# CONTROL_MODULE register map
Vendor: Texas Instruments
Registers are 32-bit, access per field, no defined reset value unless marked. A register's access mark holds for its fields unless they carry their own. Offsets are as the file gives them; [hi:lo] are bit positions; {n}, {i} and the like mark numbered series.

## CONTROL_MODULE (part 4 of 5)
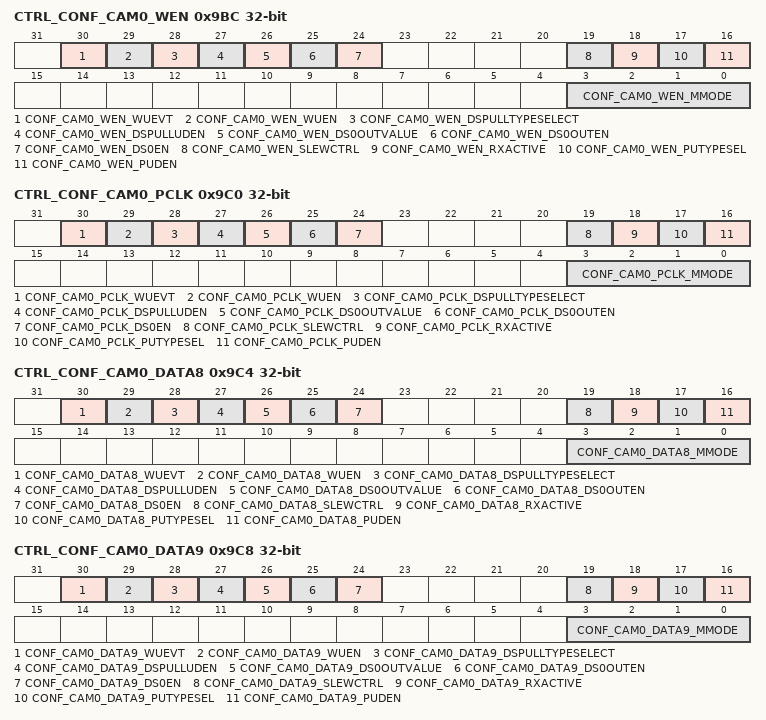
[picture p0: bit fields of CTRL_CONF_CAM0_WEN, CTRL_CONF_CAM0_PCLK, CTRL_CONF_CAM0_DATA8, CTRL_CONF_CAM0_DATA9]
0x9BC CTRL_CONF_CAM0_WEN
  [30] CONF_CAM0_WEN_WUEVT ro — Wakeup Event [[br]]0 = No event [[br]]1 = Event occurred
  [29] CONF_CAM0_WEN_WUEN rw — Wakeup enable [[br]]0 = disable [[br]]1 = enable
  [28] CONF_CAM0_WEN_DSPULLTYPESELECT rw — DS0 mode Pull-Up/Down selection [[br]]0 = Offmode Pull-Down selected [[br]]1 = Offmode Pull-Up selected
  [27] CONF_CAM0_WEN_DSPULLUDEN rw — DS0 mode Pull-Up/Down enable. [[br]]This is an active low signal. [[br]]1 = Pullup / Pulldown disabled [[br]]0 = Pullup / Pulldown enabled
  [26] CONF_CAM0_WEN_DS0OUTVALUE rw — DS0 mode output value [[br]]0 = Set value at 0 [[br]]1 = Set value at 1
  [25] CONF_CAM0_WEN_DS0OUTEN rw — DS0 mode output enable This is an active low signal [[br]]0 = Output Enable [[br]]1 = Output Disable
  [24] CONF_CAM0_WEN_DS0EN rw — DS0 mode override control [[br]]0: IO state keeps its previous state when DS0 mode is active [[br]]1: IO state is forced to OFF mode value when DS0 mode is active
  [19] CONF_CAM0_WEN_SLEWCTRL rw — Select between Faster or Slower Slew rate [[br]]0 = fast [[br]]1 = slow
  [18] CONF_CAM0_WEN_RXACTIVE rw — Input Enable Value for the PAD [[br]]0 = receiver disabled [[br]]1 = receiver enabled
  [17] CONF_CAM0_WEN_PUTYPESEL rw — Pad Pullup / Pulldown Type Selection [[br]]0 = Pulldown selected [[br]]1 = Pullup selected
  [16] CONF_CAM0_WEN_PUDEN rw — Pad Pullup / Pulldown Enable. [[br]]This is an active low signal [[br]]1 = Pullup / Pulldown disabled [[br]]0 = Pullup / Pulldown enabled
  [3:0] CONF_CAM0_WEN_MMODE rw — Pad Functional Signal Mux Select
0x9C0 CTRL_CONF_CAM0_PCLK
  [30] CONF_CAM0_PCLK_WUEVT ro — Wakeup Event [[br]]0 = No event [[br]]1 = Event occurred
  [29] CONF_CAM0_PCLK_WUEN rw — Wakeup enable [[br]]0 = disable [[br]]1 = enable
  [28] CONF_CAM0_PCLK_DSPULLTYPESELECT rw — DS0 mode Pull-Up/Down selection [[br]]0 = Offmode Pull-Down selected [[br]]1 = Offmode Pull-Up selected
  [27] CONF_CAM0_PCLK_DSPULLUDEN rw — DS0 mode Pull-Up/Down enable. [[br]]This is an active low signal. [[br]]1 = Pullup / Pulldown disabled [[br]]0 = Pullup / Pulldown enabled
  [26] CONF_CAM0_PCLK_DS0OUTVALUE rw — DS0 mode output value [[br]]0 = Set value at 0 [[br]]1 = Set value at 1
  [25] CONF_CAM0_PCLK_DS0OUTEN rw — DS0 mode output enable This is an active low signal [[br]]0 = Output Enable [[br]]1 = Output Disable
  [24] CONF_CAM0_PCLK_DS0EN rw — DS0 mode override control [[br]]0: IO state keeps its previous state when DS0 mode is active [[br]]1: IO state is forced to OFF mode value when DS0 mode is active
  [19] CONF_CAM0_PCLK_SLEWCTRL rw — Select between Faster or Slower Slew rate [[br]]0 = fast [[br]]1 = slow
  [18] CONF_CAM0_PCLK_RXACTIVE rw — Input Enable Value for the PAD [[br]]0 = receiver disabled [[br]]1 = receiver enabled
  [17] CONF_CAM0_PCLK_PUTYPESEL rw — Pad Pullup / Pulldown Type Selection [[br]]0 = Pulldown selected [[br]]1 = Pullup selected
  [16] CONF_CAM0_PCLK_PUDEN rw — Pad Pullup / Pulldown Enable. [[br]]This is an active low signal [[br]]1 = Pullup / Pulldown disabled [[br]]0 = Pullup / Pulldown enabled
  [3:0] CONF_CAM0_PCLK_MMODE rw — Pad Functional Signal Mux Select
0x9C4 CTRL_CONF_CAM0_DATA8
  [30] CONF_CAM0_DATA8_WUEVT ro — Wakeup Event [[br]]0 = No event [[br]]1 = Event occurred
  [29] CONF_CAM0_DATA8_WUEN rw — Wakeup enable [[br]]0 = disable [[br]]1 = enable
  [28] CONF_CAM0_DATA8_DSPULLTYPESELECT rw — DS0 mode Pull-Up/Down selection [[br]]0 = Offmode Pull-Down selected [[br]]1 = Offmode Pull-Up selected
  [27] CONF_CAM0_DATA8_DSPULLUDEN rw — DS0 mode Pull-Up/Down enable. [[br]]This is an active low signal. [[br]]1 = Pullup / Pulldown disabled [[br]]0 = Pullup / Pulldown enabled
  [26] CONF_CAM0_DATA8_DS0OUTVALUE rw — DS0 mode output value [[br]]0 = Set value at 0 [[br]]1 = Set value at 1
  [25] CONF_CAM0_DATA8_DS0OUTEN rw — DS0 mode output enable This is an active low signal [[br]]0 = Output Enable [[br]]1 = Output Disable
  [24] CONF_CAM0_DATA8_DS0EN rw — DS0 mode override control [[br]]0: IO state keeps its previous state when DS0 mode is active [[br]]1: IO state is forced to OFF mode value when DS0 mode is active
  [19] CONF_CAM0_DATA8_SLEWCTRL rw — Select between Faster or Slower Slew rate [[br]]0 = fast [[br]]1 = slow
  [18] CONF_CAM0_DATA8_RXACTIVE rw — Input Enable Value for the PAD [[br]]0 = receiver disabled [[br]]1 = receiver enabled
  [17] CONF_CAM0_DATA8_PUTYPESEL rw — Pad Pullup / Pulldown Type Selection [[br]]0 = Pulldown selected [[br]]1 = Pullup selected
  [16] CONF_CAM0_DATA8_PUDEN rw — Pad Pullup / Pulldown Enable. [[br]]This is an active low signal [[br]]1 = Pullup / Pulldown disabled [[br]]0 = Pullup / Pulldown enabled
  [3:0] CONF_CAM0_DATA8_MMODE rw — Pad Functional Signal Mux Select
0x9C8 CTRL_CONF_CAM0_DATA9
  [30] CONF_CAM0_DATA9_WUEVT ro — Wakeup Event [[br]]0 = No event [[br]]1 = Event occurred
  [29] CONF_CAM0_DATA9_WUEN rw — Wakeup enable [[br]]0 = disable [[br]]1 = enable
  [28] CONF_CAM0_DATA9_DSPULLTYPESELECT rw — DS0 mode Pull-Up/Down selection [[br]]0 = Offmode Pull-Down selected [[br]]1 = Offmode Pull-Up selected
  [27] CONF_CAM0_DATA9_DSPULLUDEN rw — DS0 mode Pull-Up/Down enable. [[br]]This is an active low signal. [[br]]1 = Pullup / Pulldown disabled [[br]]0 = Pullup / Pulldown enabled
  [26] CONF_CAM0_DATA9_DS0OUTVALUE rw — DS0 mode output value [[br]]0 = Set value at 0 [[br]]1 = Set value at 1
  [25] CONF_CAM0_DATA9_DS0OUTEN rw — DS0 mode output enable This is an active low signal [[br]]0 = Output Enable [[br]]1 = Output Disable
  [24] CONF_CAM0_DATA9_DS0EN rw — DS0 mode override control [[br]]0: IO state keeps its previous state when DS0 mode is active [[br]]1: IO state is forced to OFF mode value when DS0 mode is active
  [19] CONF_CAM0_DATA9_SLEWCTRL rw — Select between Faster or Slower Slew rate [[br]]0 = fast [[br]]1 = slow
  [18] CONF_CAM0_DATA9_RXACTIVE rw — Input Enable Value for the PAD [[br]]0 = receiver disabled [[br]]1 = receiver enabled
  [17] CONF_CAM0_DATA9_PUTYPESEL rw — Pad Pullup / Pulldown Type Selection [[br]]0 = Pulldown selected [[br]]1 = Pullup selected
  [16] CONF_CAM0_DATA9_PUDEN rw — Pad Pullup / Pulldown Enable. [[br]]This is an active low signal [[br]]1 = Pullup / Pulldown disabled [[br]]0 = Pullup / Pulldown enabled
  [3:0] CONF_CAM0_DATA9_MMODE rw — Pad Functional Signal Mux Select
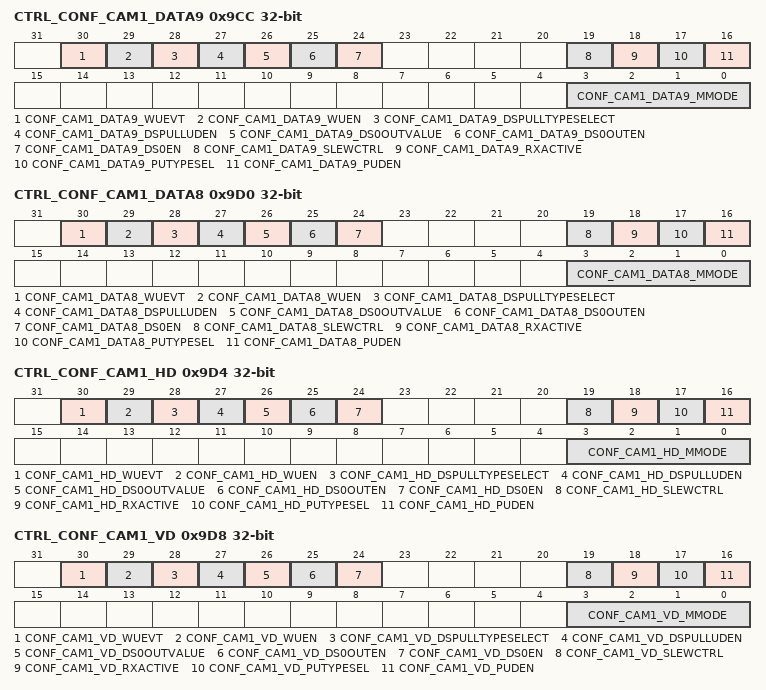
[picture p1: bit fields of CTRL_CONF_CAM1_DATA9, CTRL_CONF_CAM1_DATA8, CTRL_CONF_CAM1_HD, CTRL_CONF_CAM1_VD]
0x9CC CTRL_CONF_CAM1_DATA9
  [30] CONF_CAM1_DATA9_WUEVT ro — Wakeup Event [[br]]0 = No event [[br]]1 = Event occurred
  [29] CONF_CAM1_DATA9_WUEN rw — Wakeup enable [[br]]0 = disable [[br]]1 = enable
  [28] CONF_CAM1_DATA9_DSPULLTYPESELECT rw — DS0 mode Pull-Up/Down selection [[br]]0 = Offmode Pull-Down selected [[br]]1 = Offmode Pull-Up selected
  [27] CONF_CAM1_DATA9_DSPULLUDEN rw — DS0 mode Pull-Up/Down enable. [[br]]This is an active low signal. [[br]]1 = Pullup / Pulldown disabled [[br]]0 = Pullup / Pulldown enabled
  [26] CONF_CAM1_DATA9_DS0OUTVALUE rw — DS0 mode output value [[br]]0 = Set value at 0 [[br]]1 = Set value at 1
  [25] CONF_CAM1_DATA9_DS0OUTEN rw — DS0 mode output enable This is an active low signal [[br]]0 = Output Enable [[br]]1 = Output Disable
  [24] CONF_CAM1_DATA9_DS0EN rw — DS0 mode override control [[br]]0: IO state keeps its previous state when DS0 mode is active [[br]]1: IO state is forced to OFF mode value when DS0 mode is active
  [19] CONF_CAM1_DATA9_SLEWCTRL rw — Select between Faster or Slower Slew rate [[br]]0 = fast [[br]]1 = slow
  [18] CONF_CAM1_DATA9_RXACTIVE rw — Input Enable Value for the PAD [[br]]0 = receiver disabled [[br]]1 = receiver enabled
  [17] CONF_CAM1_DATA9_PUTYPESEL rw — Pad Pullup / Pulldown Type Selection [[br]]0 = Pulldown selected [[br]]1 = Pullup selected
  [16] CONF_CAM1_DATA9_PUDEN rw — Pad Pullup / Pulldown Enable. [[br]]This is an active low signal [[br]]1 = Pullup / Pulldown disabled [[br]]0 = Pullup / Pulldown enabled
  [3:0] CONF_CAM1_DATA9_MMODE rw — Pad Functional Signal Mux Select
0x9D0 CTRL_CONF_CAM1_DATA8
  [30] CONF_CAM1_DATA8_WUEVT ro — Wakeup Event [[br]]0 = No event [[br]]1 = Event occurred
  [29] CONF_CAM1_DATA8_WUEN rw — Wakeup enable [[br]]0 = disable [[br]]1 = enable
  [28] CONF_CAM1_DATA8_DSPULLTYPESELECT rw — DS0 mode Pull-Up/Down selection [[br]]0 = Offmode Pull-Down selected [[br]]1 = Offmode Pull-Up selected
  [27] CONF_CAM1_DATA8_DSPULLUDEN rw — DS0 mode Pull-Up/Down enable. [[br]]This is an active low signal. [[br]]1 = Pullup / Pulldown disabled [[br]]0 = Pullup / Pulldown enabled
  [26] CONF_CAM1_DATA8_DS0OUTVALUE rw — DS0 mode output value [[br]]0 = Set value at 0 [[br]]1 = Set value at 1
  [25] CONF_CAM1_DATA8_DS0OUTEN rw — DS0 mode output enable This is an active low signal [[br]]0 = Output Enable [[br]]1 = Output Disable
  [24] CONF_CAM1_DATA8_DS0EN rw — DS0 mode override control [[br]]0: IO state keeps its previous state when DS0 mode is active [[br]]1: IO state is forced to OFF mode value when DS0 mode is active
  [19] CONF_CAM1_DATA8_SLEWCTRL rw — Select between Faster or Slower Slew rate [[br]]0 = fast [[br]]1 = slow
  [18] CONF_CAM1_DATA8_RXACTIVE rw — Input Enable Value for the PAD [[br]]0 = receiver disabled [[br]]1 = receiver enabled
  [17] CONF_CAM1_DATA8_PUTYPESEL rw — Pad Pullup / Pulldown Type Selection [[br]]0 = Pulldown selected [[br]]1 = Pullup selected
  [16] CONF_CAM1_DATA8_PUDEN rw — Pad Pullup / Pulldown Enable. [[br]]This is an active low signal [[br]]1 = Pullup / Pulldown disabled [[br]]0 = Pullup / Pulldown enabled
  [3:0] CONF_CAM1_DATA8_MMODE rw — Pad Functional Signal Mux Select
0x9D4 CTRL_CONF_CAM1_HD
  [30] CONF_CAM1_HD_WUEVT ro — Wakeup Event [[br]]0 = No event [[br]]1 = Event occurred
  [29] CONF_CAM1_HD_WUEN rw — Wakeup enable [[br]]0 = disable [[br]]1 = enable
  [28] CONF_CAM1_HD_DSPULLTYPESELECT rw — DS0 mode Pull-Up/Down selection [[br]]0 = Offmode Pull-Down selected [[br]]1 = Offmode Pull-Up selected
  [27] CONF_CAM1_HD_DSPULLUDEN rw — DS0 mode Pull-Up/Down enable. [[br]]This is an active low signal. [[br]]1 = Pullup / Pulldown disabled [[br]]0 = Pullup / Pulldown enabled
  [26] CONF_CAM1_HD_DS0OUTVALUE rw — DS0 mode output value [[br]]0 = Set value at 0 [[br]]1 = Set value at 1
  [25] CONF_CAM1_HD_DS0OUTEN rw — DS0 mode output enable This is an active low signal [[br]]0 = Output Enable [[br]]1 = Output Disable
  [24] CONF_CAM1_HD_DS0EN rw — DS0 mode override control [[br]]0: IO state keeps its previous state when DS0 mode is active [[br]]1: IO state is forced to OFF mode value when DS0 mode is active
  [19] CONF_CAM1_HD_SLEWCTRL rw — Select between Faster or Slower Slew rate [[br]]0 = fast [[br]]1 = slow
  [18] CONF_CAM1_HD_RXACTIVE rw — Input Enable Value for the PAD [[br]]0 = receiver disabled [[br]]1 = receiver enabled
  [17] CONF_CAM1_HD_PUTYPESEL rw — Pad Pullup / Pulldown Type Selection [[br]]0 = Pulldown selected [[br]]1 = Pullup selected
  [16] CONF_CAM1_HD_PUDEN rw — Pad Pullup / Pulldown Enable. [[br]]This is an active low signal [[br]]1 = Pullup / Pulldown disabled [[br]]0 = Pullup / Pulldown enabled
  [3:0] CONF_CAM1_HD_MMODE rw — Pad Functional Signal Mux Select
0x9D8 CTRL_CONF_CAM1_VD
  [30] CONF_CAM1_VD_WUEVT ro — Wakeup Event [[br]]0 = No event [[br]]1 = Event occurred
  [29] CONF_CAM1_VD_WUEN rw — Wakeup enable [[br]]0 = disable [[br]]1 = enable
  [28] CONF_CAM1_VD_DSPULLTYPESELECT rw — DS0 mode Pull-Up/Down selection [[br]]0 = Offmode Pull-Down selected [[br]]1 = Offmode Pull-Up selected
  [27] CONF_CAM1_VD_DSPULLUDEN rw — DS0 mode Pull-Up/Down enable. [[br]]This is an active low signal. [[br]]1 = Pullup / Pulldown disabled [[br]]0 = Pullup / Pulldown enabled
  [26] CONF_CAM1_VD_DS0OUTVALUE rw — DS0 mode output value [[br]]0 = Set value at 0 [[br]]1 = Set value at 1
  [25] CONF_CAM1_VD_DS0OUTEN rw — DS0 mode output enable This is an active low signal [[br]]0 = Output Enable [[br]]1 = Output Disable
  [24] CONF_CAM1_VD_DS0EN rw — DS0 mode override control [[br]]0: IO state keeps its previous state when DS0 mode is active [[br]]1: IO state is forced to OFF mode value when DS0 mode is active
  [19] CONF_CAM1_VD_SLEWCTRL rw — Select between Faster or Slower Slew rate [[br]]0 = fast [[br]]1 = slow
  [18] CONF_CAM1_VD_RXACTIVE rw — Input Enable Value for the PAD [[br]]0 = receiver disabled [[br]]1 = receiver enabled
  [17] CONF_CAM1_VD_PUTYPESEL rw — Pad Pullup / Pulldown Type Selection [[br]]0 = Pulldown selected [[br]]1 = Pullup selected
  [16] CONF_CAM1_VD_PUDEN rw — Pad Pullup / Pulldown Enable. [[br]]This is an active low signal [[br]]1 = Pullup / Pulldown disabled [[br]]0 = Pullup / Pulldown enabled
  [3:0] CONF_CAM1_VD_MMODE rw — Pad Functional Signal Mux Select
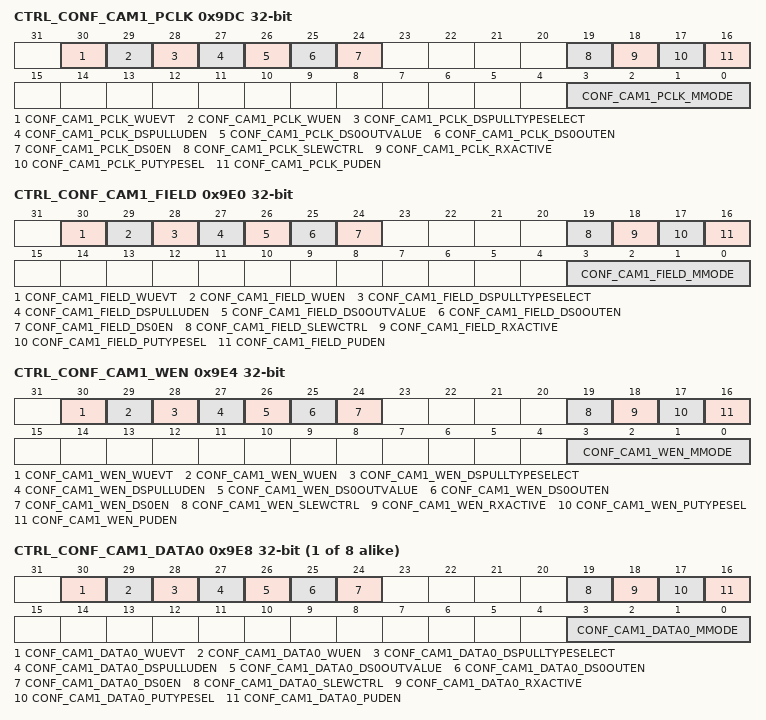
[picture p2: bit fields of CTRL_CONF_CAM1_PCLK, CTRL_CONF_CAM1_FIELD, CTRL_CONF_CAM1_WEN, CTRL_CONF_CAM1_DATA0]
0x9DC CTRL_CONF_CAM1_PCLK
  [30] CONF_CAM1_PCLK_WUEVT ro — Wakeup Event [[br]]0 = No event [[br]]1 = Event occurred
  [29] CONF_CAM1_PCLK_WUEN rw — Wakeup enable [[br]]0 = disable [[br]]1 = enable
  [28] CONF_CAM1_PCLK_DSPULLTYPESELECT rw — DS0 mode Pull-Up/Down selection [[br]]0 = Offmode Pull-Down selected [[br]]1 = Offmode Pull-Up selected
  [27] CONF_CAM1_PCLK_DSPULLUDEN rw — DS0 mode Pull-Up/Down enable. [[br]]This is an active low signal. [[br]]1 = Pullup / Pulldown disabled [[br]]0 = Pullup / Pulldown enabled
  [26] CONF_CAM1_PCLK_DS0OUTVALUE rw — DS0 mode output value [[br]]0 = Set value at 0 [[br]]1 = Set value at 1
  [25] CONF_CAM1_PCLK_DS0OUTEN rw — DS0 mode output enable This is an active low signal [[br]]0 = Output Enable [[br]]1 = Output Disable
  [24] CONF_CAM1_PCLK_DS0EN rw — DS0 mode override control [[br]]0: IO state keeps its previous state when DS0 mode is active [[br]]1: IO state is forced to OFF mode value when DS0 mode is active
  [19] CONF_CAM1_PCLK_SLEWCTRL rw — Select between Faster or Slower Slew rate [[br]]0 = fast [[br]]1 = slow
  [18] CONF_CAM1_PCLK_RXACTIVE rw — Input Enable Value for the PAD [[br]]0 = receiver disabled [[br]]1 = receiver enabled
  [17] CONF_CAM1_PCLK_PUTYPESEL rw — Pad Pullup / Pulldown Type Selection [[br]]0 = Pulldown selected [[br]]1 = Pullup selected
  [16] CONF_CAM1_PCLK_PUDEN rw — Pad Pullup / Pulldown Enable. [[br]]This is an active low signal [[br]]1 = Pullup / Pulldown disabled [[br]]0 = Pullup / Pulldown enabled
  [3:0] CONF_CAM1_PCLK_MMODE rw — Pad Functional Signal Mux Select
0x9E0 CTRL_CONF_CAM1_FIELD
  [30] CONF_CAM1_FIELD_WUEVT ro — Wakeup Event [[br]]0 = No event [[br]]1 = Event occurred
  [29] CONF_CAM1_FIELD_WUEN rw — Wakeup enable [[br]]0 = disable [[br]]1 = enable
  [28] CONF_CAM1_FIELD_DSPULLTYPESELECT rw — DS0 mode Pull-Up/Down selection [[br]]0 = Offmode Pull-Down selected [[br]]1 = Offmode Pull-Up selected
  [27] CONF_CAM1_FIELD_DSPULLUDEN rw — DS0 mode Pull-Up/Down enable. [[br]]This is an active low signal. [[br]]1 = Pullup / Pulldown disabled [[br]]0 = Pullup / Pulldown enabled
  [26] CONF_CAM1_FIELD_DS0OUTVALUE rw — DS0 mode output value [[br]]0 = Set value at 0 [[br]]1 = Set value at 1
  [25] CONF_CAM1_FIELD_DS0OUTEN rw — DS0 mode output enable This is an active low signal [[br]]0 = Output Enable [[br]]1 = Output Disable
  [24] CONF_CAM1_FIELD_DS0EN rw — DS0 mode override control [[br]]0: IO state keeps its previous state when DS0 mode is active [[br]]1: IO state is forced to OFF mode value when DS0 mode is active
  [19] CONF_CAM1_FIELD_SLEWCTRL rw — Select between Faster or Slower Slew rate [[br]]0 = fast [[br]]1 = slow
  [18] CONF_CAM1_FIELD_RXACTIVE rw — Input Enable Value for the PAD [[br]]0 = receiver disabled [[br]]1 = receiver enabled
  [17] CONF_CAM1_FIELD_PUTYPESEL rw — Pad Pullup / Pulldown Type Selection [[br]]0 = Pulldown selected [[br]]1 = Pullup selected
  [16] CONF_CAM1_FIELD_PUDEN rw — Pad Pullup / Pulldown Enable. [[br]]This is an active low signal [[br]]1 = Pullup / Pulldown disabled [[br]]0 = Pullup / Pulldown enabled
  [3:0] CONF_CAM1_FIELD_MMODE rw — Pad Functional Signal Mux Select
0x9E4 CTRL_CONF_CAM1_WEN
  [30] CONF_CAM1_WEN_WUEVT ro — Wakeup Event [[br]]0 = No event [[br]]1 = Event occurred
  [29] CONF_CAM1_WEN_WUEN rw — Wakeup enable [[br]]0 = disable [[br]]1 = enable
  [28] CONF_CAM1_WEN_DSPULLTYPESELECT rw — DS0 mode Pull-Up/Down selection [[br]]0 = Offmode Pull-Down selected [[br]]1 = Offmode Pull-Up selected
  [27] CONF_CAM1_WEN_DSPULLUDEN rw — DS0 mode Pull-Up/Down enable. [[br]]This is an active low signal. [[br]]1 = Pullup / Pulldown disabled [[br]]0 = Pullup / Pulldown enabled
  [26] CONF_CAM1_WEN_DS0OUTVALUE rw — DS0 mode output value [[br]]0 = Set value at 0 [[br]]1 = Set value at 1
  [25] CONF_CAM1_WEN_DS0OUTEN rw — DS0 mode output enable This is an active low signal [[br]]0 = Output Enable [[br]]1 = Output Disable
  [24] CONF_CAM1_WEN_DS0EN rw — DS0 mode override control [[br]]0: IO state keeps its previous state when DS0 mode is active [[br]]1: IO state is forced to OFF mode value when DS0 mode is active
  [19] CONF_CAM1_WEN_SLEWCTRL rw — Select between Faster or Slower Slew rate [[br]]0 = fast [[br]]1 = slow
  [18] CONF_CAM1_WEN_RXACTIVE rw — Input Enable Value for the PAD [[br]]0 = receiver disabled [[br]]1 = receiver enabled
  [17] CONF_CAM1_WEN_PUTYPESEL rw — Pad Pullup / Pulldown Type Selection [[br]]0 = Pulldown selected [[br]]1 = Pullup selected
  [16] CONF_CAM1_WEN_PUDEN rw — Pad Pullup / Pulldown Enable. [[br]]This is an active low signal [[br]]1 = Pullup / Pulldown disabled [[br]]0 = Pullup / Pulldown enabled
  [3:0] CONF_CAM1_WEN_MMODE rw — Pad Functional Signal Mux Select
{0x9E8+4i} CTRL_CONF_CAM1_DATA{i} (i=0..7)
  [30] CONF_CAM1_DATA{i}_WUEVT ro — Wakeup Event [[br]]0 = No event [[br]]1 = Event occurred
  [29] CONF_CAM1_DATA{i}_WUEN rw — Wakeup enable [[br]]0 = disable [[br]]1 = enable
  [28] CONF_CAM1_DATA{i}_DSPULLTYPESELECT rw — DS0 mode Pull-Up/Down selection [[br]]0 = Offmode Pull-Down selected [[br]]1 = Offmode Pull-Up selected
  [27] CONF_CAM1_DATA{i}_DSPULLUDEN rw — DS0 mode Pull-Up/Down enable. [[br]]This is an active low signal. [[br]]1 = Pullup / Pulldown disabled [[br]]0 = Pullup / Pulldown enabled
  [26] CONF_CAM1_DATA{i}_DS0OUTVALUE rw — DS0 mode output value [[br]]0 = Set value at 0 [[br]]1 = Set value at 1
  [25] CONF_CAM1_DATA{i}_DS0OUTEN rw — DS0 mode output enable This is an active low signal [[br]]0 = Output Enable [[br]]1 = Output Disable
  [24] CONF_CAM1_DATA{i}_DS0EN rw — DS0 mode override control [[br]]0: IO state keeps its previous state when DS0 mode is active [[br]]1: IO state is forced to OFF mode value when DS0 mode is active
  [19] CONF_CAM1_DATA{i}_SLEWCTRL rw — Select between Faster or Slower Slew rate [[br]]0 = fast [[br]]1 = slow
  [18] CONF_CAM1_DATA{i}_RXACTIVE rw — Input Enable Value for the PAD [[br]]0 = receiver disabled [[br]]1 = receiver enabled
  [17] CONF_CAM1_DATA{i}_PUTYPESEL rw — Pad Pullup / Pulldown Type Selection [[br]]0 = Pulldown selected [[br]]1 = Pullup selected
  [16] CONF_CAM1_DATA{i}_PUDEN rw — Pad Pullup / Pulldown Enable. [[br]]This is an active low signal [[br]]1 = Pullup / Pulldown disabled [[br]]0 = Pullup / Pulldown enabled
  [3:0] CONF_CAM1_DATA{i}_MMODE rw — Pad Functional Signal Mux Select
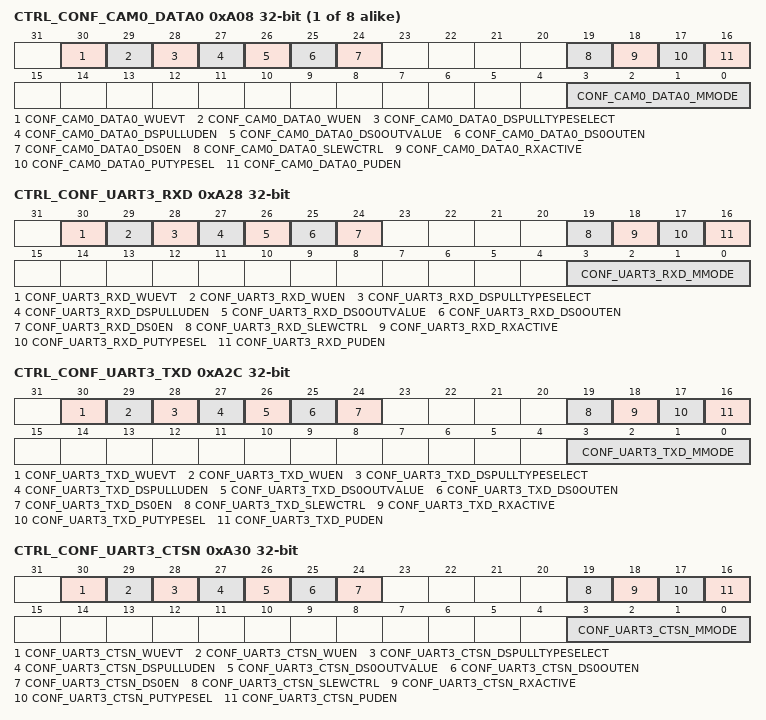
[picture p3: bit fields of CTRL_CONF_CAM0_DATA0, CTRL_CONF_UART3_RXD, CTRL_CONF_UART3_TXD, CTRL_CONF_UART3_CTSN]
{0xA08+4i} CTRL_CONF_CAM0_DATA{i} (i=0..7)
  [30] CONF_CAM0_DATA{i}_WUEVT ro — Wakeup Event [[br]]0 = No event [[br]]1 = Event occurred
  [29] CONF_CAM0_DATA{i}_WUEN rw — Wakeup enable [[br]]0 = disable [[br]]1 = enable
  [28] CONF_CAM0_DATA{i}_DSPULLTYPESELECT rw — DS0 mode Pull-Up/Down selection [[br]]0 = Offmode Pull-Down selected [[br]]1 = Offmode Pull-Up selected
  [27] CONF_CAM0_DATA{i}_DSPULLUDEN rw — DS0 mode Pull-Up/Down enable. [[br]]This is an active low signal. [[br]]1 = Pullup / Pulldown disabled [[br]]0 = Pullup / Pulldown enabled
  [26] CONF_CAM0_DATA{i}_DS0OUTVALUE rw — DS0 mode output value [[br]]0 = Set value at 0 [[br]]1 = Set value at 1
  [25] CONF_CAM0_DATA{i}_DS0OUTEN rw — DS0 mode output enable This is an active low signal [[br]]0 = Output Enable [[br]]1 = Output Disable
  [24] CONF_CAM0_DATA{i}_DS0EN rw — DS0 mode override control [[br]]0: IO state keeps its previous state when DS0 mode is active [[br]]1: IO state is forced to OFF mode value when DS0 mode is active
  [19] CONF_CAM0_DATA{i}_SLEWCTRL rw — Select between Faster or Slower Slew rate [[br]]0 = fast [[br]]1 = slow
  [18] CONF_CAM0_DATA{i}_RXACTIVE rw — Input Enable Value for the PAD [[br]]0 = receiver disabled [[br]]1 = receiver enabled
  [17] CONF_CAM0_DATA{i}_PUTYPESEL rw — Pad Pullup / Pulldown Type Selection [[br]]0 = Pulldown selected [[br]]1 = Pullup selected
  [16] CONF_CAM0_DATA{i}_PUDEN rw — Pad Pullup / Pulldown Enable. [[br]]This is an active low signal [[br]]1 = Pullup / Pulldown disabled [[br]]0 = Pullup / Pulldown enabled
  [3:0] CONF_CAM0_DATA{i}_MMODE rw — Pad Functional Signal Mux Select
0xA28 CTRL_CONF_UART3_RXD
  [30] CONF_UART3_RXD_WUEVT ro — Wakeup Event [[br]]0 = No event [[br]]1 = Event occurred
  [29] CONF_UART3_RXD_WUEN rw — Wakeup enable [[br]]0 = disable [[br]]1 = enable
  [28] CONF_UART3_RXD_DSPULLTYPESELECT rw — DS0 mode Pull-Up/Down selection [[br]]0 = Offmode Pull-Down selected [[br]]1 = Offmode Pull-Up selected
  [27] CONF_UART3_RXD_DSPULLUDEN rw — DS0 mode Pull-Up/Down enable. [[br]]This is an active low signal. [[br]]1 = Pullup / Pulldown disabled [[br]]0 = Pullup / Pulldown enabled
  [26] CONF_UART3_RXD_DS0OUTVALUE rw — DS0 mode output value [[br]]0 = Set value at 0 [[br]]1 = Set value at 1
  [25] CONF_UART3_RXD_DS0OUTEN rw — DS0 mode output enable This is an active low signal [[br]]0 = Output Enable [[br]]1 = Output Disable
  [24] CONF_UART3_RXD_DS0EN rw — DS0 mode override control [[br]]0: IO state keeps its previous state when DS0 mode is active [[br]]1: IO state is forced to OFF mode value when DS0 mode is active
  [19] CONF_UART3_RXD_SLEWCTRL rw — Select between Faster or Slower Slew rate [[br]]0 = fast [[br]]1 = slow
  [18] CONF_UART3_RXD_RXACTIVE rw — Input Enable Value for the PAD [[br]]0 = receiver disabled [[br]]1 = receiver enabled
  [17] CONF_UART3_RXD_PUTYPESEL rw — Pad Pullup / Pulldown Type Selection [[br]]0 = Pulldown selected [[br]]1 = Pullup selected
  [16] CONF_UART3_RXD_PUDEN rw — Pad Pullup / Pulldown Enable. [[br]]This is an active low signal [[br]]1 = Pullup / Pulldown disabled [[br]]0 = Pullup / Pulldown enabled
  [3:0] CONF_UART3_RXD_MMODE rw — Pad Functional Signal Mux Select
0xA2C CTRL_CONF_UART3_TXD
  [30] CONF_UART3_TXD_WUEVT ro — Wakeup Event [[br]]0 = No event [[br]]1 = Event occurred
  [29] CONF_UART3_TXD_WUEN rw — Wakeup enable [[br]]0 = disable [[br]]1 = enable
  [28] CONF_UART3_TXD_DSPULLTYPESELECT rw — DS0 mode Pull-Up/Down selection [[br]]0 = Offmode Pull-Down selected [[br]]1 = Offmode Pull-Up selected
  [27] CONF_UART3_TXD_DSPULLUDEN rw — DS0 mode Pull-Up/Down enable. [[br]]This is an active low signal. [[br]]1 = Pullup / Pulldown disabled [[br]]0 = Pullup / Pulldown enabled
  [26] CONF_UART3_TXD_DS0OUTVALUE rw — DS0 mode output value [[br]]0 = Set value at 0 [[br]]1 = Set value at 1
  [25] CONF_UART3_TXD_DS0OUTEN rw — DS0 mode output enable This is an active low signal [[br]]0 = Output Enable [[br]]1 = Output Disable
  [24] CONF_UART3_TXD_DS0EN rw — DS0 mode override control [[br]]0: IO state keeps its previous state when DS0 mode is active [[br]]1: IO state is forced to OFF mode value when DS0 mode is active
  [19] CONF_UART3_TXD_SLEWCTRL rw — Select between Faster or Slower Slew rate [[br]]0 = fast [[br]]1 = slow
  [18] CONF_UART3_TXD_RXACTIVE rw — Input Enable Value for the PAD [[br]]0 = receiver disabled [[br]]1 = receiver enabled
  [17] CONF_UART3_TXD_PUTYPESEL rw — Pad Pullup / Pulldown Type Selection [[br]]0 = Pulldown selected [[br]]1 = Pullup selected
  [16] CONF_UART3_TXD_PUDEN rw — Pad Pullup / Pulldown Enable. [[br]]This is an active low signal [[br]]1 = Pullup / Pulldown disabled [[br]]0 = Pullup / Pulldown enabled
  [3:0] CONF_UART3_TXD_MMODE rw — Pad Functional Signal Mux Select
0xA30 CTRL_CONF_UART3_CTSN
  [30] CONF_UART3_CTSN_WUEVT ro — Wakeup Event [[br]]0 = No event [[br]]1 = Event occurred
  [29] CONF_UART3_CTSN_WUEN rw — Wakeup enable [[br]]0 = disable [[br]]1 = enable
  [28] CONF_UART3_CTSN_DSPULLTYPESELECT rw — DS0 mode Pull-Up/Down selection [[br]]0 = Offmode Pull-Down selected [[br]]1 = Offmode Pull-Up selected
  [27] CONF_UART3_CTSN_DSPULLUDEN rw — DS0 mode Pull-Up/Down enable. [[br]]This is an active low signal. [[br]]1 = Pullup / Pulldown disabled [[br]]0 = Pullup / Pulldown enabled
  [26] CONF_UART3_CTSN_DS0OUTVALUE rw — DS0 mode output value [[br]]0 = Set value at 0 [[br]]1 = Set value at 1
  [25] CONF_UART3_CTSN_DS0OUTEN rw — DS0 mode output enable This is an active low signal [[br]]0 = Output Enable [[br]]1 = Output Disable
  [24] CONF_UART3_CTSN_DS0EN rw — DS0 mode override control [[br]]0: IO state keeps its previous state when DS0 mode is active [[br]]1: IO state is forced to OFF mode value when DS0 mode is active
  [19] CONF_UART3_CTSN_SLEWCTRL rw — Select between Faster or Slower Slew rate [[br]]0 = fast [[br]]1 = slow
  [18] CONF_UART3_CTSN_RXACTIVE rw — Input Enable Value for the PAD [[br]]0 = receiver disabled [[br]]1 = receiver enabled
  [17] CONF_UART3_CTSN_PUTYPESEL rw — Pad Pullup / Pulldown Type Selection [[br]]0 = Pulldown selected [[br]]1 = Pullup selected
  [16] CONF_UART3_CTSN_PUDEN rw — Pad Pullup / Pulldown Enable. [[br]]This is an active low signal [[br]]1 = Pullup / Pulldown disabled [[br]]0 = Pullup / Pulldown enabled
  [3:0] CONF_UART3_CTSN_MMODE rw — Pad Functional Signal Mux Select
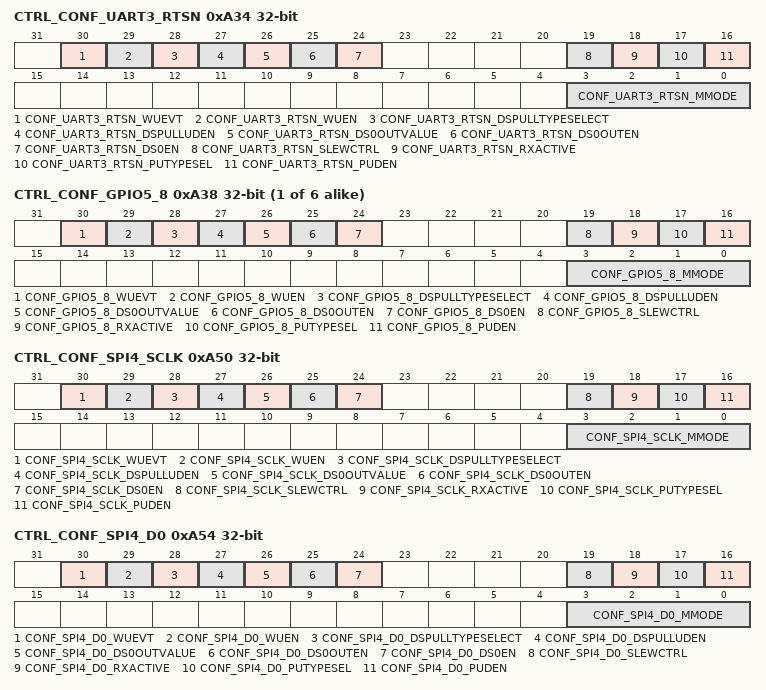
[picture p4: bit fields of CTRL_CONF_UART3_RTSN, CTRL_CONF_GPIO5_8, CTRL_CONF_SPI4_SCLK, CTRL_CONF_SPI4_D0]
0xA34 CTRL_CONF_UART3_RTSN
  [30] CONF_UART3_RTSN_WUEVT ro — Wakeup Event [[br]]0 = No event [[br]]1 = Event occurred
  [29] CONF_UART3_RTSN_WUEN rw — Wakeup enable [[br]]0 = disable [[br]]1 = enable
  [28] CONF_UART3_RTSN_DSPULLTYPESELECT rw — DS0 mode Pull-Up/Down selection [[br]]0 = Offmode Pull-Down selected [[br]]1 = Offmode Pull-Up selected
  [27] CONF_UART3_RTSN_DSPULLUDEN rw — DS0 mode Pull-Up/Down enable. [[br]]This is an active low signal. [[br]]1 = Pullup / Pulldown disabled [[br]]0 = Pullup / Pulldown enabled
  [26] CONF_UART3_RTSN_DS0OUTVALUE rw — DS0 mode output value [[br]]0 = Set value at 0 [[br]]1 = Set value at 1
  [25] CONF_UART3_RTSN_DS0OUTEN rw — DS0 mode output enable This is an active low signal [[br]]0 = Output Enable [[br]]1 = Output Disable
  [24] CONF_UART3_RTSN_DS0EN rw — DS0 mode override control [[br]]0: IO state keeps its previous state when DS0 mode is active [[br]]1: IO state is forced to OFF mode value when DS0 mode is active
  [19] CONF_UART3_RTSN_SLEWCTRL rw — Select between Faster or Slower Slew rate [[br]]0 = fast [[br]]1 = slow
  [18] CONF_UART3_RTSN_RXACTIVE rw — Input Enable Value for the PAD [[br]]0 = receiver disabled [[br]]1 = receiver enabled
  [17] CONF_UART3_RTSN_PUTYPESEL rw — Pad Pullup / Pulldown Type Selection [[br]]0 = Pulldown selected [[br]]1 = Pullup selected
  [16] CONF_UART3_RTSN_PUDEN rw — Pad Pullup / Pulldown Enable. [[br]]This is an active low signal [[br]]1 = Pullup / Pulldown disabled [[br]]0 = Pullup / Pulldown enabled
  [3:0] CONF_UART3_RTSN_MMODE rw — Pad Functional Signal Mux Select
{0xA18+4i} CTRL_CONF_GPIO5_{i} (i=8..13)
  [30] CONF_GPIO5_{i}_WUEVT ro — Wakeup Event [[br]]0 = No event [[br]]1 = Event occurred
  [29] CONF_GPIO5_{i}_WUEN rw — Wakeup enable [[br]]0 = disable [[br]]1 = enable
  [28] CONF_GPIO5_{i}_DSPULLTYPESELECT rw — DS0 mode Pull-Up/Down selection [[br]]0 = Offmode Pull-Down selected [[br]]1 = Offmode Pull-Up selected
  [27] CONF_GPIO5_{i}_DSPULLUDEN rw — DS0 mode Pull-Up/Down enable. [[br]]This is an active low signal. [[br]]1 = Pullup / Pulldown disabled [[br]]0 = Pullup / Pulldown enabled
  [26] CONF_GPIO5_{i}_DS0OUTVALUE rw — DS0 mode output value [[br]]0 = Set value at 0 [[br]]1 = Set value at 1
  [25] CONF_GPIO5_{i}_DS0OUTEN rw — DS0 mode output enable This is an active low signal [[br]]0 = Output Enable [[br]]1 = Output Disable
  [24] CONF_GPIO5_{i}_DS0EN rw — DS0 mode override control [[br]]0: IO state keeps its previous state when DS0 mode is active [[br]]1: IO state is forced to OFF mode value when DS0 mode is active
  [19] CONF_GPIO5_{i}_SLEWCTRL rw — Select between Faster or Slower Slew rate [[br]]0 = fast [[br]]1 = slow
  [18] CONF_GPIO5_{i}_RXACTIVE rw — Input Enable Value for the PAD [[br]]0 = receiver disabled [[br]]1 = receiver enabled
  [17] CONF_GPIO5_{i}_PUTYPESEL rw — Pad Pullup / Pulldown Type Selection [[br]]0 = Pulldown selected [[br]]1 = Pullup selected
  [16] CONF_GPIO5_{i}_PUDEN rw — Pad Pullup / Pulldown Enable. [[br]]This is an active low signal [[br]]1 = Pullup / Pulldown disabled [[br]]0 = Pullup / Pulldown enabled
  [3:0] CONF_GPIO5_{i}_MMODE rw — Pad Functional Signal Mux Select
0xA50 CTRL_CONF_SPI4_SCLK
  [30] CONF_SPI4_SCLK_WUEVT ro — Wakeup Event [[br]]0 = No event [[br]]1 = Event occurred
  [29] CONF_SPI4_SCLK_WUEN rw — Wakeup enable [[br]]0 = disable [[br]]1 = enable
  [28] CONF_SPI4_SCLK_DSPULLTYPESELECT rw — DS0 mode Pull-Up/Down selection [[br]]0 = Offmode Pull-Down selected [[br]]1 = Offmode Pull-Up selected
  [27] CONF_SPI4_SCLK_DSPULLUDEN rw — DS0 mode Pull-Up/Down enable. [[br]]This is an active low signal. [[br]]1 = Pullup / Pulldown disabled [[br]]0 = Pullup / Pulldown enabled
  [26] CONF_SPI4_SCLK_DS0OUTVALUE rw — DS0 mode output value [[br]]0 = Set value at 0 [[br]]1 = Set value at 1
  [25] CONF_SPI4_SCLK_DS0OUTEN rw — DS0 mode output enable This is an active low signal [[br]]0 = Output Enable [[br]]1 = Output Disable
  [24] CONF_SPI4_SCLK_DS0EN rw — DS0 mode override control [[br]]0: IO state keeps its previous state when DS0 mode is active [[br]]1: IO state is forced to OFF mode value when DS0 mode is active
  [19] CONF_SPI4_SCLK_SLEWCTRL rw — Select between Faster or Slower Slew rate [[br]]0 = fast [[br]]1 = slow
  [18] CONF_SPI4_SCLK_RXACTIVE rw — Input Enable Value for the PAD [[br]]0 = receiver disabled [[br]]1 = receiver enabled
  [17] CONF_SPI4_SCLK_PUTYPESEL rw — Pad Pullup / Pulldown Type Selection [[br]]0 = Pulldown selected [[br]]1 = Pullup selected
  [16] CONF_SPI4_SCLK_PUDEN rw — Pad Pullup / Pulldown Enable. [[br]]This is an active low signal [[br]]1 = Pullup / Pulldown disabled [[br]]0 = Pullup / Pulldown enabled
  [3:0] CONF_SPI4_SCLK_MMODE rw — Pad Functional Signal Mux Select
0xA54 CTRL_CONF_SPI4_D0
  [30] CONF_SPI4_D0_WUEVT ro — Wakeup Event [[br]]0 = No event [[br]]1 = Event occurred
  [29] CONF_SPI4_D0_WUEN rw — Wakeup enable [[br]]0 = disable [[br]]1 = enable
  [28] CONF_SPI4_D0_DSPULLTYPESELECT rw — DS0 mode Pull-Up/Down selection [[br]]0 = Offmode Pull-Down selected [[br]]1 = Offmode Pull-Up selected
  [27] CONF_SPI4_D0_DSPULLUDEN rw — DS0 mode Pull-Up/Down enable. [[br]]This is an active low signal. [[br]]1 = Pullup / Pulldown disabled [[br]]0 = Pullup / Pulldown enabled
  [26] CONF_SPI4_D0_DS0OUTVALUE rw — DS0 mode output value [[br]]0 = Set value at 0 [[br]]1 = Set value at 1
  [25] CONF_SPI4_D0_DS0OUTEN rw — DS0 mode output enable This is an active low signal [[br]]0 = Output Enable [[br]]1 = Output Disable
  [24] CONF_SPI4_D0_DS0EN rw — DS0 mode override control [[br]]0: IO state keeps its previous state when DS0 mode is active [[br]]1: IO state is forced to OFF mode value when DS0 mode is active
  [19] CONF_SPI4_D0_SLEWCTRL rw — Select between Faster or Slower Slew rate [[br]]0 = fast [[br]]1 = slow
  [18] CONF_SPI4_D0_RXACTIVE rw — Input Enable Value for the PAD [[br]]0 = receiver disabled [[br]]1 = receiver enabled
  [17] CONF_SPI4_D0_PUTYPESEL rw — Pad Pullup / Pulldown Type Selection [[br]]0 = Pulldown selected [[br]]1 = Pullup selected
  [16] CONF_SPI4_D0_PUDEN rw — Pad Pullup / Pulldown Enable. [[br]]This is an active low signal [[br]]1 = Pullup / Pulldown disabled [[br]]0 = Pullup / Pulldown enabled
  [3:0] CONF_SPI4_D0_MMODE rw — Pad Functional Signal Mux Select
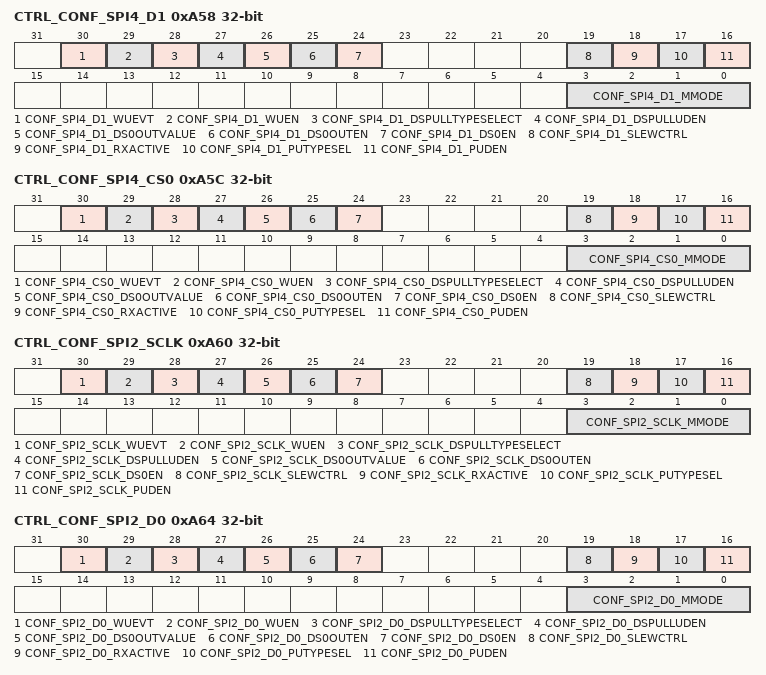
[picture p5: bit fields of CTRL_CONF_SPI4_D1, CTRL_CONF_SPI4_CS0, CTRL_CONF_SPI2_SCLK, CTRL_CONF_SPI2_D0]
0xA58 CTRL_CONF_SPI4_D1
  [30] CONF_SPI4_D1_WUEVT ro — Wakeup Event [[br]]0 = No event [[br]]1 = Event occurred
  [29] CONF_SPI4_D1_WUEN rw — Wakeup enable [[br]]0 = disable [[br]]1 = enable
  [28] CONF_SPI4_D1_DSPULLTYPESELECT rw — DS0 mode Pull-Up/Down selection [[br]]0 = Offmode Pull-Down selected [[br]]1 = Offmode Pull-Up selected
  [27] CONF_SPI4_D1_DSPULLUDEN rw — DS0 mode Pull-Up/Down enable. [[br]]This is an active low signal. [[br]]1 = Pullup / Pulldown disabled [[br]]0 = Pullup / Pulldown enabled
  [26] CONF_SPI4_D1_DS0OUTVALUE rw — DS0 mode output value [[br]]0 = Set value at 0 [[br]]1 = Set value at 1
  [25] CONF_SPI4_D1_DS0OUTEN rw — DS0 mode output enable This is an active low signal [[br]]0 = Output Enable [[br]]1 = Output Disable
  [24] CONF_SPI4_D1_DS0EN rw — DS0 mode override control [[br]]0: IO state keeps its previous state when DS0 mode is active [[br]]1: IO state is forced to OFF mode value when DS0 mode is active
  [19] CONF_SPI4_D1_SLEWCTRL rw — Select between Faster or Slower Slew rate [[br]]0 = fast [[br]]1 = slow
  [18] CONF_SPI4_D1_RXACTIVE rw — Input Enable Value for the PAD [[br]]0 = receiver disabled [[br]]1 = receiver enabled
  [17] CONF_SPI4_D1_PUTYPESEL rw — Pad Pullup / Pulldown Type Selection [[br]]0 = Pulldown selected [[br]]1 = Pullup selected
  [16] CONF_SPI4_D1_PUDEN rw — Pad Pullup / Pulldown Enable. [[br]]This is an active low signal [[br]]1 = Pullup / Pulldown disabled [[br]]0 = Pullup / Pulldown enabled
  [3:0] CONF_SPI4_D1_MMODE rw — Pad Functional Signal Mux Select
0xA5C CTRL_CONF_SPI4_CS0
  [30] CONF_SPI4_CS0_WUEVT ro — Wakeup Event [[br]]0 = No event [[br]]1 = Event occurred
  [29] CONF_SPI4_CS0_WUEN rw — Wakeup enable [[br]]0 = disable [[br]]1 = enable
  [28] CONF_SPI4_CS0_DSPULLTYPESELECT rw — DS0 mode Pull-Up/Down selection [[br]]0 = Offmode Pull-Down selected [[br]]1 = Offmode Pull-Up selected
  [27] CONF_SPI4_CS0_DSPULLUDEN rw — DS0 mode Pull-Up/Down enable. [[br]]This is an active low signal. [[br]]1 = Pullup / Pulldown disabled [[br]]0 = Pullup / Pulldown enabled
  [26] CONF_SPI4_CS0_DS0OUTVALUE rw — DS0 mode output value [[br]]0 = Set value at 0 [[br]]1 = Set value at 1
  [25] CONF_SPI4_CS0_DS0OUTEN rw — DS0 mode output enable This is an active low signal [[br]]0 = Output Enable [[br]]1 = Output Disable
  [24] CONF_SPI4_CS0_DS0EN rw — DS0 mode override control [[br]]0: IO state keeps its previous state when DS0 mode is active [[br]]1: IO state is forced to OFF mode value when DS0 mode is active
  [19] CONF_SPI4_CS0_SLEWCTRL rw — Select between Faster or Slower Slew rate [[br]]0 = fast [[br]]1 = slow
  [18] CONF_SPI4_CS0_RXACTIVE rw — Input Enable Value for the PAD [[br]]0 = receiver disabled [[br]]1 = receiver enabled
  [17] CONF_SPI4_CS0_PUTYPESEL rw — Pad Pullup / Pulldown Type Selection [[br]]0 = Pulldown selected [[br]]1 = Pullup selected
  [16] CONF_SPI4_CS0_PUDEN rw — Pad Pullup / Pulldown Enable. [[br]]This is an active low signal [[br]]1 = Pullup / Pulldown disabled [[br]]0 = Pullup / Pulldown enabled
  [3:0] CONF_SPI4_CS0_MMODE rw — Pad Functional Signal Mux Select
0xA60 CTRL_CONF_SPI2_SCLK
  [30] CONF_SPI2_SCLK_WUEVT ro — Wakeup Event [[br]]0 = No event [[br]]1 = Event occurred
  [29] CONF_SPI2_SCLK_WUEN rw — Wakeup enable [[br]]0 = disable [[br]]1 = enable
  [28] CONF_SPI2_SCLK_DSPULLTYPESELECT rw — DS0 mode Pull-Up/Down selection [[br]]0 = Offmode Pull-Down selected [[br]]1 = Offmode Pull-Up selected
  [27] CONF_SPI2_SCLK_DSPULLUDEN rw — DS0 mode Pull-Up/Down enable. [[br]]This is an active low signal. [[br]]1 = Pullup / Pulldown disabled [[br]]0 = Pullup / Pulldown enabled
  [26] CONF_SPI2_SCLK_DS0OUTVALUE rw — DS0 mode output value [[br]]0 = Set value at 0 [[br]]1 = Set value at 1
  [25] CONF_SPI2_SCLK_DS0OUTEN rw — DS0 mode output enable This is an active low signal [[br]]0 = Output Enable [[br]]1 = Output Disable
  [24] CONF_SPI2_SCLK_DS0EN rw — DS0 mode override control [[br]]0: IO state keeps its previous state when DS0 mode is active [[br]]1: IO state is forced to OFF mode value when DS0 mode is active
  [19] CONF_SPI2_SCLK_SLEWCTRL rw — Select between Faster or Slower Slew rate [[br]]0 = fast [[br]]1 = slow
  [18] CONF_SPI2_SCLK_RXACTIVE rw — Input Enable Value for the PAD [[br]]0 = receiver disabled [[br]]1 = receiver enabled
  [17] CONF_SPI2_SCLK_PUTYPESEL rw — Pad Pullup / Pulldown Type Selection [[br]]0 = Pulldown selected [[br]]1 = Pullup selected
  [16] CONF_SPI2_SCLK_PUDEN rw — Pad Pullup / Pulldown Enable. [[br]]This is an active low signal [[br]]1 = Pullup / Pulldown disabled [[br]]0 = Pullup / Pulldown enabled
  [3:0] CONF_SPI2_SCLK_MMODE rw — Pad Functional Signal Mux Select
0xA64 CTRL_CONF_SPI2_D0
  [30] CONF_SPI2_D0_WUEVT ro — Wakeup Event [[br]]0 = No event [[br]]1 = Event occurred
  [29] CONF_SPI2_D0_WUEN rw — Wakeup enable [[br]]0 = disable [[br]]1 = enable
  [28] CONF_SPI2_D0_DSPULLTYPESELECT rw — DS0 mode Pull-Up/Down selection [[br]]0 = Offmode Pull-Down selected [[br]]1 = Offmode Pull-Up selected
  [27] CONF_SPI2_D0_DSPULLUDEN rw — DS0 mode Pull-Up/Down enable. [[br]]This is an active low signal. [[br]]1 = Pullup / Pulldown disabled [[br]]0 = Pullup / Pulldown enabled
  [26] CONF_SPI2_D0_DS0OUTVALUE rw — DS0 mode output value [[br]]0 = Set value at 0 [[br]]1 = Set value at 1
  [25] CONF_SPI2_D0_DS0OUTEN rw — DS0 mode output enable This is an active low signal [[br]]0 = Output Enable [[br]]1 = Output Disable
  [24] CONF_SPI2_D0_DS0EN rw — DS0 mode override control [[br]]0: IO state keeps its previous state when DS0 mode is active [[br]]1: IO state is forced to OFF mode value when DS0 mode is active
  [19] CONF_SPI2_D0_SLEWCTRL rw — Select between Faster or Slower Slew rate [[br]]0 = fast [[br]]1 = slow
  [18] CONF_SPI2_D0_RXACTIVE rw — Input Enable Value for the PAD [[br]]0 = receiver disabled [[br]]1 = receiver enabled
  [17] CONF_SPI2_D0_PUTYPESEL rw — Pad Pullup / Pulldown Type Selection [[br]]0 = Pulldown selected [[br]]1 = Pullup selected
  [16] CONF_SPI2_D0_PUDEN rw — Pad Pullup / Pulldown Enable. [[br]]This is an active low signal [[br]]1 = Pullup / Pulldown disabled [[br]]0 = Pullup / Pulldown enabled
  [3:0] CONF_SPI2_D0_MMODE rw — Pad Functional Signal Mux Select
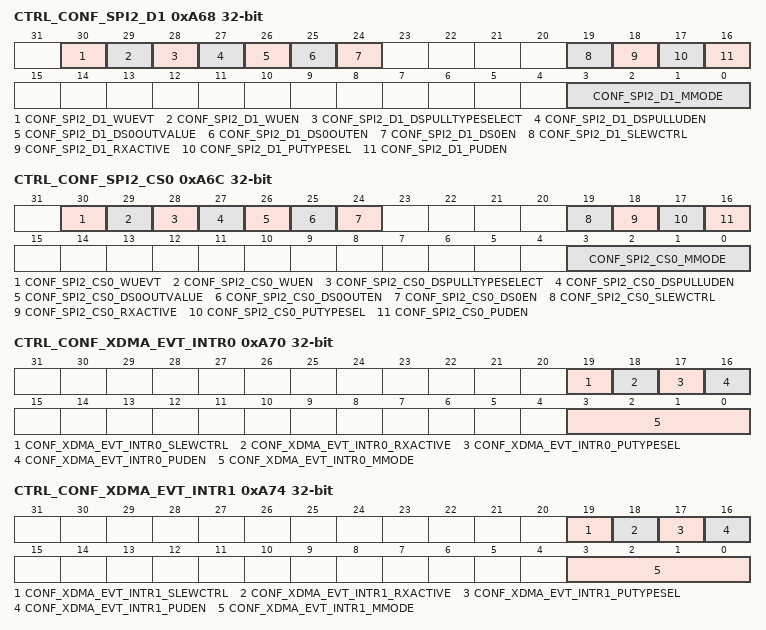
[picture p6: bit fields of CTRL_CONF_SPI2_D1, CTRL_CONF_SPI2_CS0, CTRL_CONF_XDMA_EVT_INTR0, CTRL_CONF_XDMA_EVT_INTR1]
0xA68 CTRL_CONF_SPI2_D1
  [30] CONF_SPI2_D1_WUEVT ro — Wakeup Event [[br]]0 = No event [[br]]1 = Event occurred
  [29] CONF_SPI2_D1_WUEN rw — Wakeup enable [[br]]0 = disable [[br]]1 = enable
  [28] CONF_SPI2_D1_DSPULLTYPESELECT rw — DS0 mode Pull-Up/Down selection [[br]]0 = Offmode Pull-Down selected [[br]]1 = Offmode Pull-Up selected
  [27] CONF_SPI2_D1_DSPULLUDEN rw — DS0 mode Pull-Up/Down enable. [[br]]This is an active low signal. [[br]]1 = Pullup / Pulldown disabled [[br]]0 = Pullup / Pulldown enabled
  [26] CONF_SPI2_D1_DS0OUTVALUE rw — DS0 mode output value [[br]]0 = Set value at 0 [[br]]1 = Set value at 1
  [25] CONF_SPI2_D1_DS0OUTEN rw — DS0 mode output enable This is an active low signal [[br]]0 = Output Enable [[br]]1 = Output Disable
  [24] CONF_SPI2_D1_DS0EN rw — DS0 mode override control [[br]]0: IO state keeps its previous state when DS0 mode is active [[br]]1: IO state is forced to OFF mode value when DS0 mode is active
  [19] CONF_SPI2_D1_SLEWCTRL rw — Select between Faster or Slower Slew rate [[br]]0 = fast [[br]]1 = slow
  [18] CONF_SPI2_D1_RXACTIVE rw — Input Enable Value for the PAD [[br]]0 = receiver disabled [[br]]1 = receiver enabled
  [17] CONF_SPI2_D1_PUTYPESEL rw — Pad Pullup / Pulldown Type Selection [[br]]0 = Pulldown selected [[br]]1 = Pullup selected
  [16] CONF_SPI2_D1_PUDEN rw — Pad Pullup / Pulldown Enable. [[br]]This is an active low signal [[br]]1 = Pullup / Pulldown disabled [[br]]0 = Pullup / Pulldown enabled
  [3:0] CONF_SPI2_D1_MMODE rw — Pad Functional Signal Mux Select
0xA6C CTRL_CONF_SPI2_CS0
  [30] CONF_SPI2_CS0_WUEVT ro — Wakeup Event [[br]]0 = No event [[br]]1 = Event occurred
  [29] CONF_SPI2_CS0_WUEN rw — Wakeup enable [[br]]0 = disable [[br]]1 = enable
  [28] CONF_SPI2_CS0_DSPULLTYPESELECT rw — DS0 mode Pull-Up/Down selection [[br]]0 = Offmode Pull-Down selected [[br]]1 = Offmode Pull-Up selected
  [27] CONF_SPI2_CS0_DSPULLUDEN rw — DS0 mode Pull-Up/Down enable. [[br]]This is an active low signal. [[br]]1 = Pullup / Pulldown disabled [[br]]0 = Pullup / Pulldown enabled
  [26] CONF_SPI2_CS0_DS0OUTVALUE rw — DS0 mode output value [[br]]0 = Set value at 0 [[br]]1 = Set value at 1
  [25] CONF_SPI2_CS0_DS0OUTEN rw — DS0 mode output enable This is an active low signal [[br]]0 = Output Enable [[br]]1 = Output Disable
  [24] CONF_SPI2_CS0_DS0EN rw — DS0 mode override control [[br]]0: IO state keeps its previous state when DS0 mode is active [[br]]1: IO state is forced to OFF mode value when DS0 mode is active
  [19] CONF_SPI2_CS0_SLEWCTRL rw — Select between Faster or Slower Slew rate [[br]]0 = fast [[br]]1 = slow
  [18] CONF_SPI2_CS0_RXACTIVE rw — Input Enable Value for the PAD [[br]]0 = receiver disabled [[br]]1 = receiver enabled
  [17] CONF_SPI2_CS0_PUTYPESEL rw — Pad Pullup / Pulldown Type Selection [[br]]0 = Pulldown selected [[br]]1 = Pullup selected
  [16] CONF_SPI2_CS0_PUDEN rw — Pad Pullup / Pulldown Enable. [[br]]This is an active low signal [[br]]1 = Pullup / Pulldown disabled [[br]]0 = Pullup / Pulldown enabled
  [3:0] CONF_SPI2_CS0_MMODE rw — Pad Functional Signal Mux Select
0xA70 CTRL_CONF_XDMA_EVT_INTR0
  [19] CONF_XDMA_EVT_INTR0_SLEWCTRL rw — Select between Faster or Slower Slew rate [[br]]0 = fast [[br]]1 = slow
  [18] CONF_XDMA_EVT_INTR0_RXACTIVE rw — Input Enable Value for the PAD [[br]]0 = receiver disabled [[br]]1 = receiver enabled
  [17] CONF_XDMA_EVT_INTR0_PUTYPESEL rw — Pad Pullup / Pulldown Type Selection [[br]]0 = Pulldown selected [[br]]1 = Pullup selected
  [16] CONF_XDMA_EVT_INTR0_PUDEN rw — Pad Pullup / Pulldown Enable. [[br]]This is an active low signal [[br]]1 = Pullup / Pulldown disabled [[br]]0 = Pullup / Pulldown enabled
  [3:0] CONF_XDMA_EVT_INTR0_MMODE rw — Pad Functional Signal Mux Select
0xA74 CTRL_CONF_XDMA_EVT_INTR1
  [19] CONF_XDMA_EVT_INTR1_SLEWCTRL rw — Select between Faster or Slower Slew rate [[br]]0 = fast [[br]]1 = slow
  [18] CONF_XDMA_EVT_INTR1_RXACTIVE rw — Input Enable Value for the PAD [[br]]0 = receiver disabled [[br]]1 = receiver enabled
  [17] CONF_XDMA_EVT_INTR1_PUTYPESEL rw — Pad Pullup / Pulldown Type Selection [[br]]0 = Pulldown selected [[br]]1 = Pullup selected
  [16] CONF_XDMA_EVT_INTR1_PUDEN rw — Pad Pullup / Pulldown Enable. [[br]]This is an active low signal [[br]]1 = Pullup / Pulldown disabled [[br]]0 = Pullup / Pulldown enabled
  [3:0] CONF_XDMA_EVT_INTR1_MMODE rw — Pad Functional Signal Mux Select
